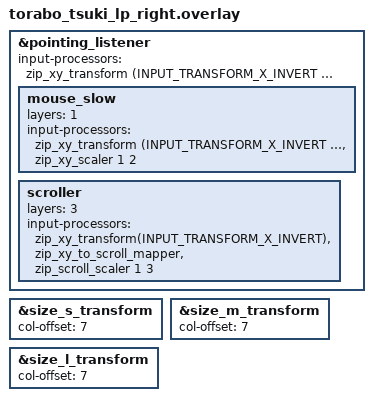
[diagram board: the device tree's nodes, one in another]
#define TORABO_TSUKI_LP_RIGHT 1
#define TORABO_TSUKI_LP_MATRIX_COL_OFFSET 7

#include "torabo_tsuki_lp.dtsi"
#include <input/processors.dtsi>
#include <dt-bindings/zmk/input_transform.h>

#if !defined(TORABO_LIVE_TRACKBALL)
&pointing_listener {
    input-processors = <&zip_xy_transform (INPUT_TRANSFORM_X_INVERT | INPUT_TRANSFORM_Y_INVERT)>;

    mouse_slow {
        layers = <1>;
        input-processors = <
            &zip_xy_transform (INPUT_TRANSFORM_X_INVERT | INPUT_TRANSFORM_Y_INVERT)
            &zip_xy_scaler 1 2
        >;
    };

    scroller {
        layers = <3>;
        input-processors = <
            &zip_xy_transform(INPUT_TRANSFORM_X_INVERT)
            &zip_xy_to_scroll_mapper
            &zip_scroll_scaler 1 3 
        >;
    };
};
#endif

&size_s_transform {
    col-offset = <7>;
};

&size_m_transform {
    col-offset = <7>;
};

&size_l_transform {
    col-offset = <7>;
};
